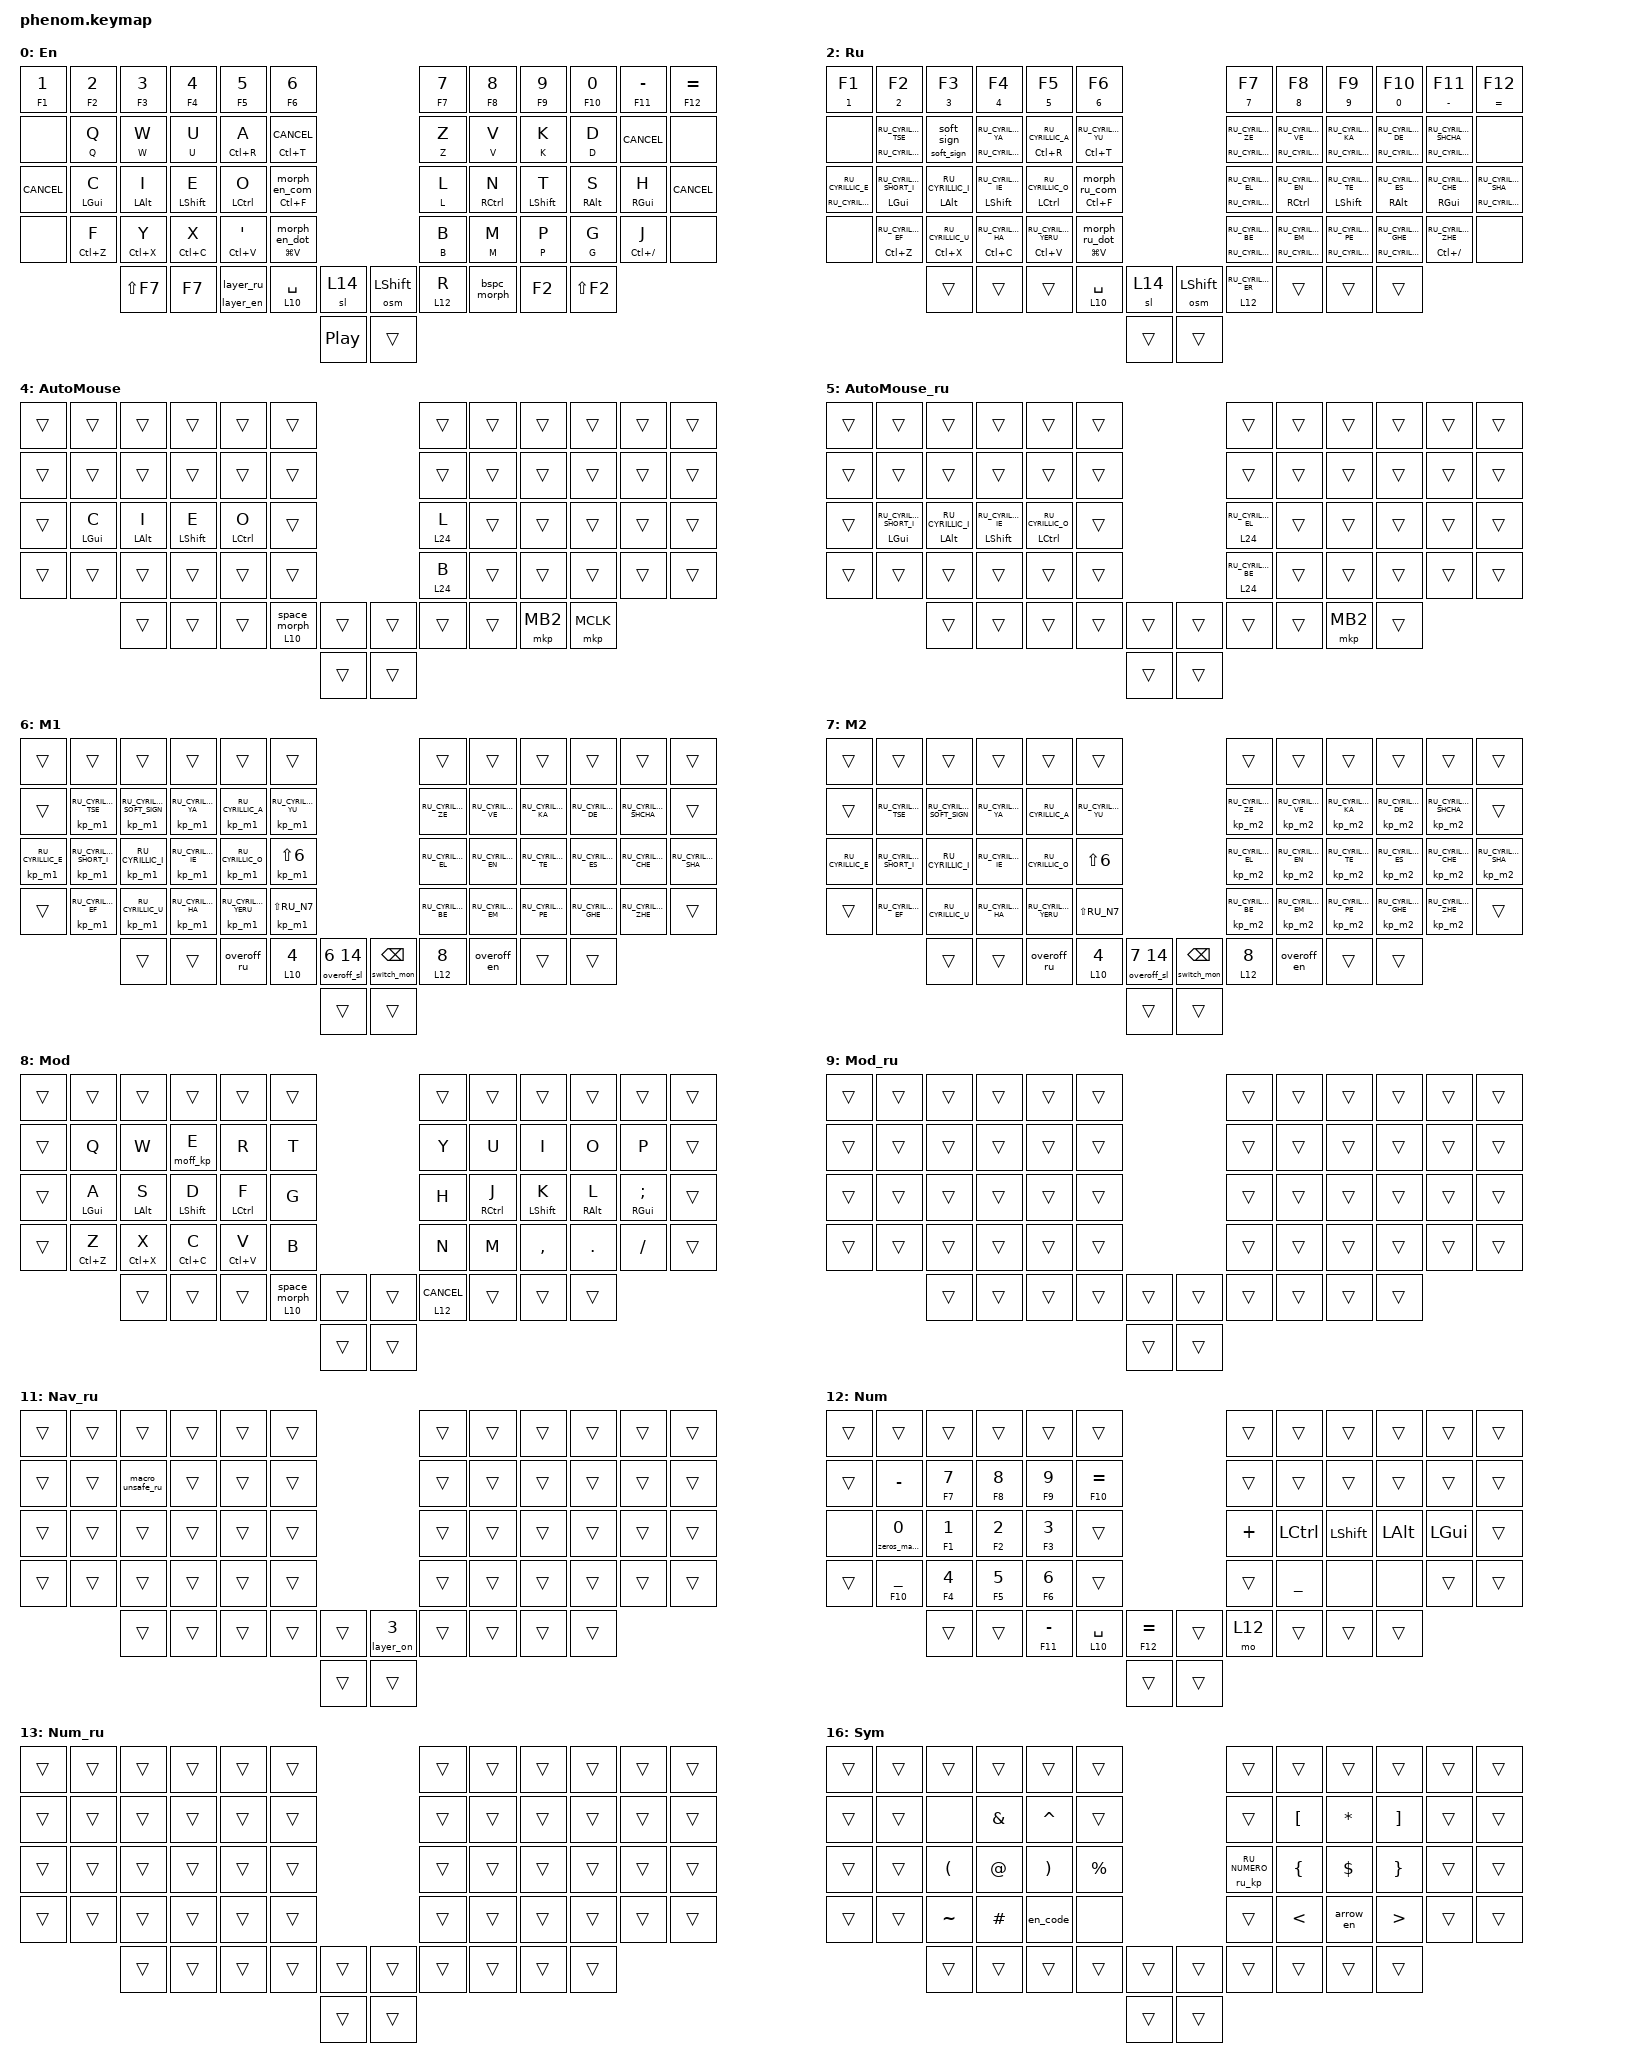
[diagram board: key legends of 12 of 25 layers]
#include "keys_ru.h"
#include <dt-bindings/zmk/behaviors.h>
#include <dt-bindings/zmk/input_transform.h>
#include <behaviors/mouse_key_toggle.dtsi>
#include <input/processors.dtsi>
#include <zephyr/dt-bindings/input/input-event-codes.h>
#include <zmk-input-inertia/input/processor/input_inertia.dtsi>
#include <behaviors.dtsi>
#include <dt-bindings/zmk/bt.h>
#include <dt-bindings/zmk/keys.h>
#include <dt-bindings/zmk/outputs.h>
#include <dt-bindings/zmk/pointing.h>

#define ZMK_POINTING_DEFAULT_SCRL_VAL 20
#define ZMK_POINTING_DEFAULT_MOVE_VAL 125

&mt {
    flavor = "tap-preferred";
    bindings = <&moff_tap>, <&moff_tap>;

    tapping-term-ms = <200>;
};

&lt {
    flavor = "balanced";
    bindings = <&mo>, <&moff_tap>;

    tapping-term-ms = <200>;
};

&sl {
    release-after-ms = <5000>;
    ignore-modifiers;
};

&sk {
    release-after-ms = <30000>;
    quick-release;
};

&msc {
    acceleration-exponent = <0>;
    time-to-max-speed-ms = <50>;
};

&mmv {
    acceleration-exponent = <0>;
    time-to-max-speed-ms = <50>;
};

&key_repeat { usage-pages = <HID_USAGE_KEY HID_USAGE_CONSUMER>; };

/ {
    combos {
        compatible = "zmk,combos";

        combo_ctrl_ent {
            bindings = <&long_kp LC(ENTER)>;
            key-positions = <>;
            require-prior-idle-ms = <30>;
        };

        combo_enter {
            bindings = <&long_kp ENTER>;
            key-positions = <>;
            require-prior-idle-ms = <30>;
        };

        combo_tab {
            bindings = <&long_kp TAB>;
            key-positions = <>;
            require-prior-idle-ms = <30>;
            timeout-ms = <30>;
        };

        combo_esc {
            bindings = <&kp_overoff ESC>;
            key-positions = <>;
            require-prior-idle-ms = <30>;
        };

        combo_ru {
            bindings = <&layer_ru>;
            key-positions = <>;
            require-prior-idle-ms = <30>;
            timeout-ms = <30>;
        };

        combo_en {
            bindings = <&layer_en>;
            key-positions = <>;
            require-prior-idle-ms = <30>;
            timeout-ms = <30>;
        };

        combo_osl_sym_en {
            bindings = <&sl 16>;
            key-positions = <>;
            require-prior-idle-ms = <50>;
            layers = <0 1 16>;
            timeout-ms = <30>;
        };

        combo_lessgreater_en {
            bindings = <&less_greater_en>;
            require-prior-idle-ms = <20>;
            key-positions = <43 45>;
            layers = <0 1 16 4>;
        };

        combo_osl_sym_ru {
            bindings = <&sl 17>;
            key-positions = <>;
            require-prior-idle-ms = <50>;
            layers = <2 3 17>;
            timeout-ms = <30>;
        };

        combo_lessgreater_ru {
            bindings = <&less_greater_ru>;
            key-positions = <43 45>;
            require-prior-idle-ms = <30>;
            layers = <2 3>;
        };

        combo_braces_en {
            bindings = <&braces_en>;
            key-positions = <31 33>;
            require-prior-idle-ms = <20>;
            layers = <0 1 16 4>;
            timeout-ms = <30>;
        };

        combo_asterisk_ru {
            bindings = <&kp RU_ASTERISK>;
            key-positions = <>;
            layers = <2 3 17 13 5>;
        };

        combo_asterisk_en {
            bindings = <&kp ASTERISK>;
            key-positions = <>;
            layers = <0 1 12 16 4>;
        };

        combo_capsword_en {
            bindings = <&layer_on 1>;
            key-positions = <>;
            layers = <0 1>;
        };

        combo_osl_fn {
            bindings = <&sl 18>;
            key-positions = <38 40>;
        };

        combo_osl_os {
            bindings = <&sl 19>;
            key-positions = <37 38>;
        };

        combo_capsword_ru {
            bindings = <&layer_on 3>;
            key-positions = <>;
            layers = <2 3>;
        };

        combo_minus {
            bindings = <&kp MINUS>;
            key-positions = <>;
        };

        parentheses {
            bindings = <&parentheses>;
            key-positions = <26 28>;
            require-prior-idle-ms = <20>;
            timeout-ms = <30>;
        };

        combo_braces_ru {
            bindings = <&braces_ru>;
            key-positions = <31 33>;
            layers = <2 3 17 5>;
            require-prior-idle-ms = <20>;
            timeout-ms = <30>;
        };

        combo_brackets_en {
            bindings = <&brackets_en>;
            key-positions = <19 21>;
            layers = <0 1 16 4>;
            timeout-ms = <30>;
            require-prior-idle-ms = <30>;
        };

        combo_brackets_ru {
            bindings = <&brackets_ru>;
            key-positions = <19 21>;
            layers = <2 3 17 5>;
        };

        combo_equal {
            bindings = <&kp EQUAL>;
            key-positions = <>;
        };

        combo_quotes_en {
            bindings = <&quote_morph_en>;
            key-positions = <44 43>;
            layers = <0 1 12 16 4 8 10 14 19>;
        };

        combo_quotes_ru {
            bindings = <&quote_morph_ru>;
            key-positions = <43 44>;
            layers = <2 3 17 13 9 5 11 15 20>;
        };

        combo_slash_ru {
            bindings = <&slash_morph_ru>;
            key-positions = <19 20>;
            layers = <2 3 13 17 5 9 11 15 20>;
        };

        combo_slash_en {
            bindings = <&slash_morph_en>;
            key-positions = <19 20>;
            layers = <0 1 12 16 4 8 10 14 19>;
        };

        combo_arrow_ru {
            bindings = <&arrow_ru>;
            key-positions = <>;
            layers = <2 3 13 17 5 9 11 15 20>;
        };

        combo_arrow_en {
            bindings = <&arrow_en>;
            key-positions = <>;
            layers = <0 1 12 16 4 8 10 14 19>;
        };

        combo_mclick {
            bindings = <&mkp MB3>;
            key-positions = <15 14>;
            layers = <4 5 14 15 23>;
            timeout-ms = <50>;
        };

        combo_lclick {
            bindings = <&click>;
            key-positions = <>;
            layers = <4 5 14 15 23>;
            timeout-ms = <50>;
        };

        combo_rclick {
            bindings = <&mkp MB2>;
            key-positions = <39 38>;
            layers = <4 5 14 15 23>;
            timeout-ms = <50>;
        };

        combo_shft_click {
            bindings = <&mod_click LEFT_SHIFT>;
            key-positions = <>;
            layers = <4 5 14 15>;
            timeout-ms = <50>;
        };

        combo_cmd_click {
            bindings = <&mod_click LCTRL>;
            key-positions = <>;
            layers = <4 5 14 15 23>;
            timeout-ms = <50>;
        };

        combo_cmd_shift_click {
            bindings = <&mod_click LS(LCTRL)>;
            key-positions = <>;
            layers = <4 5 14 15 23>;
            timeout-ms = <50>;
        };

        combo_grave_en {
            bindings = <&kp GRAVE>;
            key-positions = <43 44 45>;
            layers = <0 1 12 16 4 8 10 14 19>;
        };

        combo_pipe_en {
            bindings = <&kp PIPE>;
            key-positions = <19 20 21>;
            layers = <0 1 12 16 4 8 10 14 19>;
        };

        combo_squote_en {
            bindings = <&kp SINGLE_QUOTE>;
            key-positions = <44 45>;
            layers = <0 1 12 16 4 8 10 14 19>;
        };

        combo_bslash_en {
            bindings = <&kp BACKSLASH>;
            key-positions = <20 21>;
            layers = <0 1 12 16 4 8 10 14 19>;
        };

        combo_bslash_ru {
            bindings = <&kp RU_BACKSLASH>;
            key-positions = <20 21>;
            layers = <2 3 13 17 5 9 11 15 20>;
        };

        combo_pipe_ru {
            bindings = <&en_kp PIPE>;
            key-positions = <20 21 19>;
            layers = <2 3 13 17 5 9 11 15 20>;
        };

        combo_squote_ru {
            bindings = <&en_kp SINGLE_QUOTE>;
            key-positions = <44 45>;
            layers = <2 3 13 17 5 9 11 15 20>;
        };

        combo_grave_ru {
            bindings = <&en_kp GRAVE>;
            key-positions = <44 45 43>;
            layers = <2 3 13 17 5 9 11 15 20>;
        };

        combo_colon_ru {
            bindings = <&kp RU_COLON>;
            key-positions = <38 39 40>;
            layers = <2 3 13 17 5 9 11 15 20>;
        };

        combo_semi_ru {
            bindings = <&kp RU_SEMI>;
            key-positions = <26 27 28>;
            layers = <2 3 13 17 5 9 11 15 20>;
        };

        combo_colon_en {
            bindings = <&kp COLON>;
            key-positions = <38 40 39>;
            layers = <0 1 12 16 4 8 10 14 19>;
        };

        combo_semi_en {
            bindings = <&kp SEMI>;
            key-positions = <26 27 28>;
            layers = <0 1 12 16 4 8 10 14 19>;
        };
    };

    macros {
        layer_ru: layer_ru {
            compatible = "zmk,behavior-macro";
            #binding-cells = <0>;
            bindings = <&to 2>, <&macro_tap_time 50>, <&kp LS(LC(N8))>;

            label = "LAYER_RU";
            tap-ms = <1>;
            wait-ms = <0>;
        };

        layer_en: layer_en {
            compatible = "zmk,behavior-macro";
            #binding-cells = <0>;
            bindings = <&to 0>, <&macro_tap_time 50>, <&kp LS(LC(N9))>;

            label = "LAYER_EN";
            tap-ms = <1>;
            wait-ms = <0>;
        };

        lg_ru: lg_ru {
            compatible = "zmk,behavior-macro";
            #binding-cells = <0>;
            bindings = <&kp LS(LC(N8))>;
            label = "LG_RU";
            tap-ms = <50>;
        };

        lg_en: lg_en {
            compatible = "zmk,behavior-macro";
            #binding-cells = <0>;
            bindings = <&kp LS(LC(N9))>;
            label = "LG_EN";
            tap-ms = <50>;
        };

        en_kp: en_kp {
            compatible = "zmk,behavior-macro-one-param";
            #binding-cells = <1>;
            bindings = <&kp LS(LC(N9)) &macro_param_1to1 &kp MACRO_PLACEHOLDER &kp LS(LC(N8))>;
            label = "EN_KP";
            tap-ms = <50>;
        };

        ru_kp: ru_kp {
            compatible = "zmk,behavior-macro-one-param";
            #binding-cells = <1>;
            bindings = <&kp LS(LC(N8)) &macro_param_1to1 &kp MACRO_PLACEHOLDER &kp LS(LC(N9))>;
            label = "RU_KP";
            tap-ms = <50>;
        };

        mouse_off: mouse_off {
            compatible = "zmk,behavior-macro";
            #binding-cells = <0>;
            bindings = <&kp LC(LS(F9))>;
            label = "MOUSE_OFF";
        };

        free: free {
            compatible = "zmk,behavior-macro";
            #binding-cells = <0>;
            bindings = <&kp LC(LS(F10))>;
            label = "FREE";
        };

        overlay: overlay {
            compatible = "zmk,behavior-macro";
            #binding-cells = <0>;
            bindings = <&kp LC(LS(F11))>;
            label = "OVERLAY";
        };

        en_code: en_code_block {
            compatible = "zmk,behavior-macro";
            #binding-cells = <0>;
            bindings = <&kp GRAVE &kp GRAVE &kp GRAVE &kp RETURN &kp RET &kp GRAVE &kp GRAVE &kp GRAVE &kp HOME &kp LEFT>;
            label = "EN_CODE_BLOCK";
            tap-ms = <50>;
        };

        ru_code: ru_code {
            compatible = "zmk,behavior-macro";
            #binding-cells = <0>;
            bindings = <&lg_en &kp GRAVE &kp GRAVE &kp GRAVE &kp RETURN &kp RET &kp GRAVE &kp GRAVE &kp GRAVE &kp HOME &kp LEFT &lg_ru>;
            label = "RU_CODE";
            tap-ms = <50>;
            wait-ms = <10>;
        };

        ru_cw_off: ru_cw_off {
            compatible = "zmk,behavior-macro-one-param";
            #binding-cells = <1>;
            bindings = <&to 2 &macro_param_1to1 &kp MACRO_PLACEHOLDER>;
            label = "RU_CW_OFF";
            wait-ms = <0>;
            tap-ms = <0>;
        };

        en_cw_off: en_cw_off {
            compatible = "zmk,behavior-macro-one-param";
            #binding-cells = <1>;
            bindings = <&to 0 &macro_param_1to1 &kp MACRO_PLACEHOLDER>;
            label = "EN_CW_OFF";
            wait-ms = <0>;
            tap-ms = <0>;
        };

        zeros_macro: zeros_macro {
            compatible = "zmk,behavior-macro";
            #binding-cells = <0>;
            bindings = <&kp N0 &kp N0 &kp N0 &kp N0 &kp N0 &kp N0>;
            label = "ZEROS_MACRO";
        };

        ml: ml {
            compatible = "zmk,behavior-macro-one-param";
            #binding-cells = <1>;
            bindings =
                <&layer_off 4 &layer_on 8 &macro_param_1to1 &key_on MACRO_PLACEHOLDER>,
                <&macro_pause_for_release>,
                <&macro_param_1to1 &key_off MACRO_PLACEHOLDER &layer_off 8>;

            label = "ML";
            wait-ms = <0>;
            tap-ms = <0>;
        };

        braces_en: braces_en {
            compatible = "zmk,behavior-macro";
            #binding-cells = <0>;
            bindings =
                <&kp LEFT_BRACE &kp RIGHT_BRACE &kp LEFT>,
                <&macro_tap_time 1>,
                <&layer_off 4>;

            label = "BRACES_EN";
            tap-ms = <50>;
        };

        braces_ru: braces_ru {
            compatible = "zmk,behavior-macro";
            #binding-cells = <0>;
            bindings =
                <&lg_en &kp LEFT_BRACE &kp RIGHT_BRACE &kp LEFT &lg_ru>,
                <&macro_tap_time 1>,
                <&layer_off 4>;

            label = "BRACES_RU";
            tap-ms = <50>;
        };

        brackets_en: brackets_en {
            compatible = "zmk,behavior-macro";
            #binding-cells = <0>;
            bindings =
                <&kp LEFT_BRACKET &kp RIGHT_BRACKET &kp LEFT_ARROW>,
                <&macro_tap_time 1>,
                <&layer_off 4>;

            label = "BRACKETS_EN";
            tap-ms = <50>;
        };

        brackets_ru: brackets_ru {
            compatible = "zmk,behavior-macro";
            #binding-cells = <0>;
            bindings =
                <&lg_en &kp LEFT_BRACKET &kp RIGHT_BRACKET &kp LEFT_ARROW &lg_ru>,
                <&macro_tap_time 1>,
                <&layer_off 4>;

            label = "BRACKETS_RU";
            tap-ms = <50>;
        };

        parentheses: parentheses {
            compatible = "zmk,behavior-macro";
            #binding-cells = <0>;
            bindings =
                <&kp LEFT_PARENTHESIS &kp RIGHT_PARENTHESIS &kp LEFT_ARROW>,
                <&macro_tap_time 1>,
                <&layer_off 4>;

            label = "PARENTHESES";
            tap-ms = <50>;
        };

        less_greater_en: less_greater_en {
            compatible = "zmk,behavior-macro";
            #binding-cells = <0>;
            bindings =
                <&kp LESS_THAN &kp GREATER_THAN &kp LEFT>,
                <&macro_tap_time 1>,
                <&layer_off 4>;

            label = "LESS_GREATER_EN";
            tap-ms = <50>;
        };

        less_greater_ru: less_greater_ru {
            compatible = "zmk,behavior-macro";
            #binding-cells = <0>;
            bindings =
                <&lg_en &kp LESS_THAN &kp GREATER_THAN &kp LEFT_ARROW &lg_ru>,
                <&macro_press>,
                <&layer_off 4>;

            label = "LESS_GREATER_RU";
            tap-ms = <50>;
        };

        alt_spc_ru: alt_spc_ru {
            compatible = "zmk,behavior-macro";
            #binding-cells = <0>;
            bindings = <&kp LA(SPACE) &layer_en>;
            label = "ALT_SPC_RU";
        };

        testops: testops {
            compatible = "zmk,behavior-macro";
            #binding-cells = <0>;
            bindings =
                <&kp LS(LC(LG(F7)))>,
                <&macro_wait_time 100>,
                <&kp LEFT_ARROW &kp LS(LC(LG(F8)))>;

            label = "TESTOPS";
            wait-ms = <350>;
            tap-ms = <150>;
        };

        long_kp: long_kp {
            compatible = "zmk,behavior-macro-one-param";
            #binding-cells = <1>;
            bindings =
                <&macro_press>,
                <&macro_param_1to1 &kp MACRO_PLACEHOLDER>,
                <&macro_pause_for_release>,
                <&macro_release>,
                <&macro_param_1to1 &kp MACRO_PLACEHOLDER>;

            label = "LONG_KP";
            wait-ms = <40>;
        };

        bt_set: bt_set {
            compatible = "zmk,behavior-macro-one-param";
            #binding-cells = <1>;
            bindings = <&out OUT_BLE &macro_param_1to2 &bt BT_SEL MACRO_PLACEHOLDER>;
            label = "BT_SET";
            tap-ms = <20>;
        };

        arrow_en: arrow_en {
            compatible = "zmk,behavior-macro";
            #binding-cells = <0>;
            bindings =
                <&kp MINUS &kp GREATER_THAN>,
                <&macro_tap_time 1>,
                <&layer_off 4>;

            label = "ARROW_EN";
            tap-ms = <50>;
        };

        arrow_ru: arrow_ru {
            compatible = "zmk,behavior-macro";
            #binding-cells = <0>;
            bindings =
                <&lg_en &arrow_en &lg_ru>,
                <&macro_tap_time 1>,
                <&layer_off 4>;

            label = "ARROW_RU";
            tap-ms = <50>;
        };

        bt_set_en: bt_set_en {
            compatible = "zmk,behavior-macro-one-param";
            #binding-cells = <1>;
            bindings = <&macro_param_1to1 &bt_set MACRO_PLACEHOLDER &layer_off 19 &lg_en &lg_en>;
            label = "BT_SET_en";
            wait-ms = <45>;
            tap-ms = <50>;
        };

        one_shot: one_shot {
            compatible = "zmk,behavior-macro-one-param";
            #binding-cells = <1>;
            bindings =
                <&macro_param_1to1 &sk MACRO_PLACEHOLDER>,
                <&macro_pause_for_release>,
                <&kp K_CANCEL>;

            label = "ONE_SHOT";
            tap-ms = <1>;
            wait-ms = <0>;
        };

        bt_set_ru: bt_set_ru {
            compatible = "zmk,behavior-macro-one-param";
            #binding-cells = <1>;
            bindings = <&macro_param_1to1 &bt_set MACRO_PLACEHOLDER &layer_off 19 &lg_ru &lg_ru>;
            label = "BT_SET_RU";
            wait-ms = <45>;
            tap-ms = <50>;
        };

        vm_lang_ru: vm_lang {
            compatible = "zmk,behavior-macro-one-param";
            #binding-cells = <1>;
            bindings = <&macro_param_1to1 &kp MACRO_PLACEHOLDER &lg_ru &lg_ru>;
            label = "VM_LANG";
            wait-ms = <100>;
            tap-ms = <100>;
        };

        vm_lang_en: vm_lang_en {
            compatible = "zmk,behavior-macro-one-param";
            #binding-cells = <1>;
            bindings = <&macro_param_1to1 &kp MACRO_PLACEHOLDER &lg_en &lg_en>;
            label = "VM_LANG_EN";
            wait-ms = <100>;
            tap-ms = <100>;
        };

        ms_free: ms_free {
            compatible = "zmk,behavior-macro";
            #binding-cells = <0>;
            bindings =
                <&mouse_off>,
                <&macro_tap_time 1>,
                <&layer_on 0 &layer_off 6 &layer_off 7 &layer_off 4>;

            label = "MS_FREE";
            wait-ms = <0>;
        };

        ms_over: ms_over {
            compatible = "zmk,behavior-macro";
            #binding-cells = <0>;
            bindings =
                <&overlay>,
                <&macro_tap_time 1>,
                <&layer_on 6 &layer_off 0 &layer_off 4>;

            label = "MS_OVER";
            wait-ms = <0>;
        };

        kp_to: kp_to {
            compatible = "zmk,behavior-macro-two-param";
            #binding-cells = <2>;
            bindings = <&macro_param_1to1 &kp MACRO_PLACEHOLDER &macro_param_2to1 &to MACRO_PLACEHOLDER>;
            label = "KP_TO";
        };

        kp_m2: kp_m2 {
            compatible = "zmk,behavior-macro-one-param";
            #binding-cells = <1>;
            bindings =
                <&layer_on 0 &layer_off 7>,
                <&macro_tap_time 15>,
                <&macro_param_1to1 &kp MACRO_PLACEHOLDER>;

            label = "KP_M2";
            tap-ms = <1>;
            wait-ms = <0>;
        };

        mouse_back: mouse_back {
            compatible = "zmk,behavior-macro";
            #binding-cells = <0>;
            bindings =
                <&kp TAB>,
                <&macro_tap_time 1>,
                <&layer_on 6 &layer_off 7>;

            label = "MOUSE_BACK";
        };

        alt_spc_en: alt_spc_en {
            compatible = "zmk,behavior-macro";
            #binding-cells = <0>;
            bindings = <&kp LA(SPACE) &layer_en>;
            label = "ALT_SPC_EN";
            tap-ms = <50>;
        };

        kp_free: kp_free {
            compatible = "zmk,behavior-macro-one-param";
            #binding-cells = <1>;
            bindings = <&macro_param_1to1 &kp MACRO_PLACEHOLDER &layer_on 0>;
            label = "KP_FREE";
        };

        kp_m1: kp_m1 {
            compatible = "zmk,behavior-macro-one-param";
            #binding-cells = <1>;
            bindings =
                <&layer_on 7 &layer_off 6>,
                <&macro_tap_time 15>,
                <&macro_param_1to1 &kp MACRO_PLACEHOLDER>;

            label = "KP_M1";
            tap-ms = <1>;
            wait-ms = <0>;
        };

        overoff_sl: overoff_sl {
            compatible = "zmk,behavior-macro-two-param";
            #binding-cells = <2>;
            bindings = <&mouse_off &macro_param_1to1 &layer_off MACRO_PLACEHOLDER &macro_param_2to1 &sl MACRO_PLACEHOLDER>;
            label = "OVEROFF_SL";
        };

        ms_set: ms_set {
            compatible = "zmk,behavior-macro";
            #binding-cells = <0>;
            bindings =
                <&kp SPACE &kp RU_CYRILLIC_I>,
                <&macro_wait_time 0>,
                <&kp RU_CYRILLIC_VE>,
                <&macro_tap_time 1>,
                <&layer_on 0 &layer_off 6 &layer_off 7>;

            label = "MS_SET";
        };

        macro_unsafe_en: macro_unsafe_en {
            compatible = "zmk,behavior-macro";
            #binding-cells = <0>;
            bindings = <&kp T &kp H &kp I &kp S &kp I &kp S &kp U &kp N &kp S &kp A &kp F &kp E>;
            label = "MACRO_UNSAFE_EN";
            wait-ms = <30>;
            tap-ms = <50>;
        };

        macro_unsafe_ru: macro_unsafe_ru {
            compatible = "zmk,behavior-macro";
            #binding-cells = <0>;
            bindings = <&lg_en &kp T &kp H &kp I &kp S &kp I &kp S &kp U &kp N &kp S &kp A &kp F &kp E &lg_ru>;
            label = "MACRO_UNSAFE_RU";
            wait-ms = <30>;
            tap-ms = <50>;
        };

        mml: mml {
            compatible = "zmk,behavior-macro-one-param";
            #binding-cells = <1>;
            bindings =
                <&macro_param_1to1 &key_on MACRO_PLACEHOLDER &layer_on 0>,
                <&macro_pause_for_release>,
                <&macro_param_1to1 &key_off MACRO_PLACEHOLDER &layer_off 0>;

            label = "MML";
            wait-ms = <0>;
            tap-ms = <0>;
        };

        moff_kp: moff_kp {
            compatible = "zmk,behavior-macro-one-param";
            #binding-cells = <1>;
            bindings =
                <&layer_off 4 &macro_param_1to1 &key_on MACRO_PLACEHOLDER>,
                <&macro_pause_for_release>,
                <&macro_param_1to1 &key_off MACRO_PLACEHOLDER>;

            label = "MOFF_KP";
            wait-ms = <0>;
            tap-ms = <0>;
        };

        cmd_scroll: cmd_scroll {
            compatible = "zmk,behavior-macro-one-param";
            #binding-cells = <1>;
            bindings =
                <&macro_press>,
                <&kp LEFT_GUI &macro_param_1to1 &mscl MACRO_PLACEHOLDER>,
                <&macro_pause_for_release>,
                <&macro_release>,
                <&macro_param_1to1 &mscl MACRO_PLACEHOLDER &kp LEFT_GUI>;

            label = "CMD_SCROLL";
            wait-ms = <0>;
        };

        mkpl: mkpl {
            compatible = "zmk,behavior-macro-one-param";
            #binding-cells = <1>;
            bindings =
                <&macro_press>,
                <&macro_param_1to1 &mkp MACRO_PLACEHOLDER>,
                <&macro_pause_for_release>,
                <&macro_release>,
                <&macro_param_1to1 &mkp MACRO_PLACEHOLDER>;

            label = "MKPL";
            wait-ms = <50>;
        };

        mmvl: mmvl {
            compatible = "zmk,behavior-macro-one-param";
            #binding-cells = <1>;
            bindings =
                <&macro_press>,
                <&macro_param_1to1 &mmv MACRO_PLACEHOLDER>,
                <&macro_pause_for_release>,
                <&macro_release>,
                <&macro_param_1to1 &mmv MACRO_PLACEHOLDER>;

            label = "MMVL";
            wait-ms = <125>;
        };

        mscl: mscl {
            compatible = "zmk,behavior-macro-one-param";
            #binding-cells = <1>;
            bindings =
                <&macro_press>,
                <&macro_param_1to1 &msc MACRO_PLACEHOLDER>,
                <&macro_pause_for_release>,
                <&macro_release>,
                <&macro_param_1to1 &msc MACRO_PLACEHOLDER>;

            label = "MSCL";
            wait-ms = <100>;
        };

        mod_layer: mod_layer {
            compatible = "zmk,behavior-macro-two-param";
            #binding-cells = <2>;
            bindings =
                <&macro_param_1to1 &key_on MACRO_PLACEHOLDER &macro_param_2to1 &layer_on MACRO_PLACEHOLDER>,
                <&macro_pause_for_release>,
                <&macro_param_2to1 &layer_off MACRO_PLACEHOLDER &macro_param_1to1 &key_off MACRO_PLACEHOLDER>;

            label = "MOD_LAYER";
            wait-ms = <0>;
            tap-ms = <1>;
        };

        esc_over_off: esc_over_off {
            compatible = "zmk,behavior-macro";
            #binding-cells = <0>;
            bindings =
                <&macro_press>,
                <&long_kp ESC>,
                <&macro_pause_for_release>,
                <&macro_release>,
                <&long_kp ESC>,
                <&macro_tap_time 1>,
                <&layer_off 6 &layer_off 7>;

            label = "ESC_OVER_OFF";
            wait-ms = <0>;
        };

        switch_mon: switch_mon {
            compatible = "zmk,behavior-macro-one-param";
            #binding-cells = <1>;
            bindings = <&macro_param_1to1 &kp MACRO_PLACEHOLDER &layer_on 6 &layer_off 7>;
            label = "SWITCH_MON";
            wait-ms = <0>;
        };

        lkp_moff: lkp_moff {
            compatible = "zmk,behavior-macro-one-param";
            #binding-cells = <1>;
            bindings =
                <&layer_off 4>,
                <&macro_wait_time 30>,
                <&macro_press>,
                <&macro_param_1to1 &kp MACRO_PLACEHOLDER>,
                <&macro_pause_for_release>,
                <&macro_release>,
                <&macro_param_1to1 &kp MACRO_PLACEHOLDER>;

            label = "LKP_MOFF";
            wait-ms = <0>;
            tap-ms = <1>;
        };

        mouse_mod: mouse_mod {
            compatible = "zmk,behavior-macro-one-param";
            #binding-cells = <1>;
            bindings =
                <&macro_press>,
                <&mo 0 &macro_param_1to1 &kp MACRO_PLACEHOLDER>,
                <&macro_pause_for_release>,
                <&macro_release>,
                <&macro_param_1to1 &kp MACRO_PLACEHOLDER &mo 0>;

            label = "MOUSE_MOD";
        };

        left_ctrl: sm_left {
            compatible = "zmk,behavior-macro-one-param";
            #binding-cells = <1>;
            bindings =
                <&macro_press>,
                <&macro_param_1to1 &mo MACRO_PLACEHOLDER &mmvl MOVE_LEFT>,
                <&macro_pause_for_release>,
                <&macro_release>,
                <&mmvl MOVE_LEFT &macro_param_1to1 &mo MACRO_PLACEHOLDER>;

            label = "SM_LEFT";
            wait-ms = <0>;
            tap-ms = <1>;
        };

        down_shift: sm_down {
            compatible = "zmk,behavior-macro-one-param";
            #binding-cells = <1>;
            bindings =
                <&macro_press>,
                <&macro_param_1to1 &mo MACRO_PLACEHOLDER &mdown_morph>,
                <&macro_pause_for_release>,
                <&macro_release>,
                <&mdown_morph &macro_param_1to1 &mo MACRO_PLACEHOLDER>;

            label = "SM_DOWN";
            wait-ms = <0>;
            tap-ms = <1>;
        };

        right_alt: right_alt {
            compatible = "zmk,behavior-macro-one-param";
            #binding-cells = <1>;
            bindings =
                <&macro_press>,
                <&macro_param_1to1 &mo MACRO_PLACEHOLDER &mright_morph>,
                <&macro_pause_for_release>,
                <&macro_release>,
                <&mright_morph &macro_param_1to1 &mo MACRO_PLACEHOLDER>;

            label = "RIGHT_ALT";
            wait-ms = <0>;
            tap-ms = <1>;
        };

        over_ms_free: over_ms_free {
            compatible = "zmk,behavior-macro";
            #binding-cells = <0>;
            bindings = <&mouse_off>, <&macro_tap_time 1>, <&ms_free>;

            label = "OVER_MS_FREE";
            wait-ms = <0>;
        };

        kp_overoff: esc_msoff {
            compatible = "zmk,behavior-macro-one-param";
            #binding-cells = <1>;
            bindings =
                <&layer_off 6 &layer_off 7>,
                <&macro_tap_time 75>,
                <&macro_param_1to1 &kp MACRO_PLACEHOLDER>;

            label = "ESC_MSOFF";
            wait-ms = <0>;
            tap-ms = <1>;
        };

        overoff_ru: overoff_ru {
            compatible = "zmk,behavior-macro";
            #binding-cells = <0>;
            bindings =
                <&mouse_off>,
                <&macro_tap_time 1>,
                <&to 2>,
                <&macro_tap_time 30>,
                <&kp LS(LC(N8))>;

            label = "OVEROFF_RU";
        };

        overoff_en: overoff_en {
            compatible = "zmk,behavior-macro";
            #binding-cells = <0>;
            bindings =
                <&mouse_off>,
                <&macro_tap_time 1>,
                <&to 0>,
                <&macro_tap_time 30>,
                <&kp LS(LC(N9))>;

            label = "OVEROFF_EN";
        };

        mod_click: mod_click {
            compatible = "zmk,behavior-macro-one-param";
            #binding-cells = <1>;
            bindings = <&macro_param_1to1 &key_on MACRO_PLACEHOLDER &mkp LCLK &macro_param_1to1 &key_off MACRO_PLACEHOLDER>;
            label = "MOD_CLICK";
        };

        mkp_moff: mkp_moff {
            compatible = "zmk,behavior-macro-one-param";
            #binding-cells = <1>;
            bindings =
                <&layer_off 4>,
                <&macro_wait_time 40>,
                <&macro_press>,
                <&macro_param_1to1 &mkp MACRO_PLACEHOLDER>,
                <&macro_pause_for_release>,
                <&macro_release>,
                <&macro_param_1to1 &mkp MACRO_PLACEHOLDER>;

            label = "MKP_MOFF";
            tap-ms = <1>;
            wait-ms = <0>;
        };

        osm: osm {
            compatible = "zmk,behavior-macro-one-param";
            #binding-cells = <1>;
            bindings =
                <&macro_param_1to1 &sk MACRO_PLACEHOLDER>,
                <&macro_pause_for_release>;

            label = "OSM";
            tap-ms = <1>;
            wait-ms = <0>;
        };

        tap: tap {
            compatible = "zmk,behavior-macro-one-param";
            #binding-cells = <1>;
            bindings =
                <&macro_param_1to1 &kp MACRO_PLACEHOLDER>,
                <&macro_pause_for_release>;

            label = "TAP";
            tap-ms = <30>;
        };

        moff_tap: moff_tap {
            compatible = "zmk,behavior-macro-one-param";
            #binding-cells = <1>;
            bindings =
                <&layer_off 4>,
                <&macro_tap_time 100>,
                <&macro_param_1to1 &kp MACRO_PLACEHOLDER>,
                <&macro_pause_for_release>;

            label = "MOFF_TAP";
            tap-ms = <0>;
            wait-ms = <0>;
        };

        click: click {
            compatible = "zmk,behavior-macro";
            #binding-cells = <0>;
            bindings =
                <&macro_press>,
                <&mo 21 &mkp MB1>,
                <&macro_pause_for_release>,
                <&macro_release>,
                <&mkp MB1 &mo 21>;

            label = "CLICK";
            wait-ms = <0>;
            tap-ms = <0>;
        };
    };

    behaviors {
        layer_off: layer_off {
            compatible = "zmk,behavior-toggle-layer";
            label = "LAYER_OFF";
            #binding-cells = <1>;
            toggle-mode = "off";
        };

        hrm: hrm {
            compatible = "zmk,behavior-hold-tap";
            label = "HRM";
            bindings = <&kp>, <&kp>;

            #binding-cells = <2>;
            tapping-term-ms = <200>;
            flavor = "balanced";
            hold-while-undecided;
        };

        hrm_slow: hrm_slow {
            compatible = "zmk,behavior-hold-tap";
            label = "HRM_SLOW";
            bindings = <&kp>, <&kp>;

            #binding-cells = <2>;
            flavor = "balanced";
            tapping-term-ms = <200>;
            hold-while-undecided;
        };

        ru_lt_cw_off: ru_lt_cw_off {
            compatible = "zmk,behavior-hold-tap";
            label = "RU_LT_CW_OFF";
            bindings = <&mo>, <&ru_cw_off>;

            #binding-cells = <2>;
            tapping-term-ms = <200>;
            flavor = "balanced";
        };

        en_lt_cw_off: en_lt_cw_off {
            compatible = "zmk,behavior-hold-tap";
            label = "EN_LT_CW_OFF";
            bindings = <&mo>, <&en_cw_off>;

            #binding-cells = <2>;
            tapping-term-ms = <200>;
            flavor = "balanced";
        };

        bspc_morph: bspc_morph {
            compatible = "zmk,behavior-mod-morph";
            label = "BSPC_MORPH";
            bindings = <&kp BACKSPACE>, <&kp DELETE>;

            #binding-cells = <0>;
            mods = <(MOD_LALT)>;
        };

        key_on: key_on {
            compatible = "zmk,behavior-key-toggle";
            label = "KEY_ON";
            #binding-cells = <1>;
        };

        key_off: key_off {
            compatible = "zmk,behavior-key-toggle";
            label = "KEY_OFF";
            #binding-cells = <1>;
            toggle-mode = "off";
        };

        hrml: hrml {
            compatible = "zmk,behavior-hold-tap";
            label = "HRML";
            bindings = <&ml>, <&moff_kp>;

            #binding-cells = <2>;
            tapping-term-ms = <200>;
            flavor = "balanced";
            hold-trigger-key-positions = <13 14 17 25 26 27 28 29 37 38 39 40 41 15 18 19 21 22 30 31 32 33 34 42 43 44 45 46 20 51 55 54>;
        };

        layer_on: layer_on {
            compatible = "zmk,behavior-toggle-layer";
            label = "LAYER_ON";
            #binding-cells = <1>;
            toggle-mode = "on";
        };

        hrml_slow: hrml_slow {
            compatible = "zmk,behavior-hold-tap";
            label = "HRML_SLOW";
            bindings = <&ml>, <&moff_tap>;

            #binding-cells = <2>;
            tapping-term-ms = <200>;
            flavor = "tap-preferred";
        };

        soft_sign: soft_sign {
            compatible = "zmk,behavior-mod-morph";
            label = "SOFT_SIGN";
            bindings =
                <&moff_kp RU_CYRILLIC_SOFT_SIGN>,
                <&moff_kp RU_CYRILLIC_HARD_SIGN>;

            #binding-cells = <0>;
            mods = <(MOD_LSFT)>;
        };

        en_dot_excl: en_dot_excl {
            compatible = "zmk,behavior-mod-morph";
            label = "EN_DOT_EXCL";
            bindings = <&morph_en_dot>, <&en_cw_off COLON>;

            #binding-cells = <0>;
            mods = <(MOD_RALT|MOD_RGUI)>;
        };

        en_com_ques: en_com_ques {
            compatible = "zmk,behavior-mod-morph";
            label = "EN_COM_QUES";
            bindings = <&morph_en_com>, <&en_cw_off SEMI>;

            #binding-cells = <0>;
            mods = <(MOD_RALT|MOD_RGUI)>;
        };

        ru_dot_excl: ru_dot_excl {
            compatible = "zmk,behavior-mod-morph";
            label = "RU_DOT_EXCL";
            bindings = <&morph_ru_dot>, <&ru_cw_off RU_COLON>;

            #binding-cells = <0>;
            mods = <(MOD_RALT|MOD_RGUI)>;
        };

        ru_com_ques: ru_com_ques {
            compatible = "zmk,behavior-mod-morph";
            label = "RU_COM_QUES";
            bindings = <&morph_ru_com>, <&ru_cw_off RU_SEMI>;

            #binding-cells = <0>;
            mods = <(MOD_RALT|MOD_RGUI)>;
        };

        ru_dot_mt: ru_dot_mt {
            compatible = "zmk,behavior-hold-tap";
            label = "RU_DOT_MT";
            bindings = <&moff_tap>, <&morph_ru_dot>;

            #binding-cells = <2>;
            tapping-term-ms = <200>;
            flavor = "tap-preferred";
        };

        ru_com_mt: ru_com_mt {
            compatible = "zmk,behavior-hold-tap";
            label = "RU_COM_MT";
            bindings = <&moff_tap>, <&morph_ru_com>;

            #binding-cells = <2>;
            tapping-term-ms = <200>;
            flavor = "tap-preferred";
        };

        en_com_mt: en_com_mt {
            compatible = "zmk,behavior-hold-tap";
            label = "EN_COM_MT";
            bindings = <&moff_tap>, <&morph_en_com>;

            #binding-cells = <2>;
            tapping-term-ms = <200>;
            flavor = "balanced";
        };

        en_dot_mt: en_dot_mt {
            compatible = "zmk,behavior-hold-tap";
            label = "EN_DOT_MT";
            bindings = <&moff_tap>, <&morph_en_dot>;

            #binding-cells = <2>;
            tapping-term-ms = <200>;
            flavor = "balanced";
        };

        space_morph: space_morph {
            compatible = "zmk,behavior-mod-morph";
            label = "SPACE_MORPH";
            bindings = <&moff_tap SPACE>, <&moff_tap TAB>;

            #binding-cells = <0>;
            mods = <(MOD_RSFT|MOD_LALT|MOD_LSFT|MOD_RALT|MOD_LCTL|MOD_RGUI|MOD_RCTL|MOD_LGUI)>;
            keep-mods = <(MOD_LSFT|MOD_RSFT|MOD_LALT|MOD_RALT|MOD_LCTL|MOD_RGUI|MOD_LGUI|MOD_RCTL)>;
        };

        caps_soft_sign: caps_soft_sign {
            compatible = "zmk,behavior-mod-morph";
            label = "CAPS_SOFT_SIGN";
            bindings =
                <&moff_kp LS(RU_CYRILLIC_SOFT_SIGN)>,
                <&moff_kp LS(RU_CYRILLIC_HARD_SIGN)>;

            #binding-cells = <0>;
            mods = <(MOD_LSFT)>;
        };

        space_lt: space_lt {
            compatible = "zmk,behavior-hold-tap";
            label = "SPACE_LT";
            bindings = <&mo>, <&space_morph>;

            #binding-cells = <2>;
            tapping-term-ms = <200>;
            flavor = "balanced";
        };

        mod_dtap: mod_dtap {
            compatible = "zmk,behavior-hold-tap";
            label = "MOD_DTAP";
            bindings = <&kp>, <&kp>;

            #binding-cells = <2>;
            tapping-term-ms = <200>;
            flavor = "hold-preferred";
        };

        hrosm_l: hrosm_l {
            compatible = "zmk,behavior-hold-tap";
            label = "HROSM_L";
            bindings = <&moff_kp>, <&moff_kp>;

            #binding-cells = <2>;
            tapping-term-ms = <200>;
            flavor = "balanced";
            hold-trigger-key-positions = <18 30 42 43 44 45 54 31 19 20 32 21 33 34 22 46 35 53>;
        };

        hrosm_r: hrosm_r {
            compatible = "zmk,behavior-hold-tap";
            label = "HROSM_R";
            bindings = <&kp>, <&moff_tap>;

            #binding-cells = <2>;
            tapping-term-ms = <200>;
            flavor = "balanced";
        };

        vm_en: vm_en {
            compatible = "zmk,behavior-hold-tap";
            label = "VM_EN";
            bindings = <&vm_lang_en>, <&vm_lang_en>;

            #binding-cells = <2>;
            tapping-term-ms = <200>;
            flavor = "tap-preferred";
        };

        vm_ru: vm_ru {
            compatible = "zmk,behavior-hold-tap";
            label = "VM_RU";
            bindings = <&vm_lang_ru>, <&vm_lang_ru>;

            #binding-cells = <2>;
            tapping-term-ms = <200>;
            flavor = "tap-preferred";
        };

        back_num: back_num {
            compatible = "zmk,behavior-hold-tap";
            label = "BACK_NUM";
            bindings = <&mo>, <&mouse_back>;

            #binding-cells = <2>;
            tapping-term-ms = <200>;
            flavor = "balanced";
        };

        slash_morph_ru: slash_morph_ru {
            compatible = "zmk,behavior-mod-morph";
            label = "SLASH_MORPH_RU";
            bindings = <&morph_pipe_ru>, <&kp RU_BACKSLASH>;

            #binding-cells = <0>;
            mods = <(MOD_LSFT)>;
        };

        slash_morph_en: slash_morph_en {
            compatible = "zmk,behavior-mod-morph";
            label = "SLASH_MORPH_EN";
            bindings = <&morph_pipe_en>, <&kp BACKSLASH>;

            #binding-cells = <0>;
            mods = <(MOD_LSFT)>;
        };

        quote_morph_ru: quote_morph_ru {
            compatible = "zmk,behavior-mod-morph";
            label = "QUOTE_MORPH_RU";
            bindings = <&kp RU_DOUBLE_QUOTES>, <&en_kp SINGLE_QUOTE>;

            #binding-cells = <0>;
            mods = <(MOD_LSFT)>;
        };

        quote_morph_en: quote_morph_en {
            compatible = "zmk,behavior-mod-morph";
            label = "QUOTE_MORPH_EN";
            bindings = <&kp DOUBLE_QUOTES>, <&kp SINGLE_QUOTE>;

            #binding-cells = <0>;
            mods = <(MOD_LSFT)>;
        };

        morph_en_dot: morph_en_dot {
            compatible = "zmk,behavior-mod-morph";
            label = "MORPH_EN_DOT";
            bindings = <&en_cw_off DOT>, <&en_cw_off EXCL>;

            #binding-cells = <0>;
            mods = <(MOD_LSFT)>;
        };

        morph_en_com: morph_en_com {
            compatible = "zmk,behavior-mod-morph";
            label = "MORPH_EN_COM";
            bindings = <&en_cw_off COMMA>, <&en_cw_off QUESTION>;

            #binding-cells = <0>;
            mods = <(MOD_LSFT)>;
        };

        morph_ru_dot: morph_ru_dot {
            compatible = "zmk,behavior-mod-morph";
            label = "MORPH_RU_DOT";
            bindings = <&ru_cw_off RU_DOT>, <&ru_cw_off RU_EXCL>;

            #binding-cells = <0>;
            mods = <(MOD_LSFT)>;
        };

        morph_ru_com: morph_ru_com {
            compatible = "zmk,behavior-mod-morph";
            label = "MORPH_RU_COM";
            bindings = <&ru_cw_off RU_COMMA>, <&ru_cw_off RU_QUESTION>;

            #binding-cells = <0>;
            mods = <(MOD_LSFT)>;
        };

        morph_quotes_ru: morph_quotes_ru {
            compatible = "zmk,behavior-mod-morph";
            label = "MORPH_QUOTES_RU";
            bindings = <&kp RU_DQT>, <&en_kp GRAVE>;

            #binding-cells = <0>;
            mods = <(MOD_RALT|MOD_LALT)>;
        };

        morph_quotes_en: morph_quotes_en {
            compatible = "zmk,behavior-mod-morph";
            label = "MORPH_QUOTES_EN";
            bindings = <&kp DQT>, <&kp GRAVE>;

            #binding-cells = <0>;
            mods = <(MOD_RALT|MOD_LALT)>;
        };

        morph_pipe_ru: morph_pipe_ru {
            compatible = "zmk,behavior-mod-morph";
            label = "MORPH_PIPE_RU";
            bindings = <&kp RU_SLASH>, <&en_kp PIPE>;

            #binding-cells = <0>;
            mods = <(MOD_LALT|MOD_RALT)>;
        };

        morph_pipe_en: morph_pipe_en {
            compatible = "zmk,behavior-mod-morph";
            label = "MORPH_PIPE_EN";
            bindings = <&kp SLASH>, <&kp PIPE>;

            #binding-cells = <0>;
            mods = <(MOD_RALT|MOD_LALT)>;
        };

        nav_set: nav_set {
            compatible = "zmk,behavior-hold-tap";
            label = "NAV_SET";
            bindings = <&mo>, <&ms_set>;

            #binding-cells = <2>;
            tapping-term-ms = <200>;
            flavor = "balanced";
        };

        mdown_morph: mdown_morph {
            compatible = "zmk,behavior-mod-morph";
            label = "MDOWN_MORPH";
            bindings = <&mmvl MOVE_DOWN>, <&moff_kp K>;

            #binding-cells = <0>;
            mods = <(MOD_LCTL)>;
            keep-mods = <(MOD_LCTL)>;
        };

        mright_morph: mright_morph {
            compatible = "zmk,behavior-mod-morph";
            label = "MRIGHT_MORPH";
            bindings = <&mmvl MOVE_RIGHT>, <&moff_kp L>;

            #binding-cells = <0>;
            mods = <(MOD_LCTL)>;
            keep-mods = <(MOD_LCTL)>;
        };

        ms_space: ms_space {
            compatible = "zmk,behavior-hold-tap";
            label = "MS_SPACE";
            bindings = <&mo>, <&space_morph>;

            #binding-cells = <2>;
            tapping-term-ms = <200>;
            flavor = "balanced";
            hold-while-undecided;
        };

        click_layer: click_layer {
            compatible = "zmk,behavior-sticky-key";
            label = "CLICK_LAYER";
            bindings = <&mo>;
            #binding-cells = <1>;
            release-after-ms = <1000>;
            quick-release;
        };

        zero: zero {
            compatible = "zmk,behavior-hold-tap";
            label = "ZERO";
            bindings = <&zeros_macro>, <&kp>;

            #binding-cells = <2>;
            tapping-term-ms = <200>;
            flavor = "tap-preferred";
        };

        bspc_lt: bspc_lt {
            compatible = "zmk,behavior-hold-tap";
            label = "BSPC_LT";
            bindings = <&mo>, <&bspc_morph>;

            #binding-cells = <2>;
            flavor = "balanced";
            tapping-term-ms = <200>;
        };

        soft: soft {
            compatible = "zmk,behavior-hold-tap";
            label = "SOFT";
            bindings = <&soft_sign>, <&soft_sign>;

            #binding-cells = <2>;
            tapping-term-ms = <200>;
            flavor = "tap-preferred";
        };

        soft_caps: soft_caps {
            compatible = "zmk,behavior-hold-tap";
            label = "SOFT_CAPS";
            bindings = <&caps_soft_sign>, <&caps_soft_sign>;

            #binding-cells = <2>;
            tapping-term-ms = <200>;
            flavor = "tap-preferred";
        };

        mmt: mmt {
            compatible = "zmk,behavior-hold-tap";
            label = "MMT";
            bindings = <&tap>, <&moff_tap>;

            #binding-cells = <2>;
            tapping-term-ms = <220>;
            flavor = "tap-preferred";
        };

        hrml_left: hrml_left {
            compatible = "zmk,behavior-hold-tap";
            label = "HRML_LEFT";
            bindings = <&ml>, <&moff_tap>;

            #binding-cells = <2>;
            tapping-term-ms = <200>;
            flavor = "balanced";
            hold-trigger-key-positions = <40 6 7 8 9 10 11>;
        };

        hrml_right: hrml_right {
            compatible = "zmk,behavior-hold-tap";
            label = "HRML_RIGHT";
            bindings = <&ml>, <&moff_kp>;

            #binding-cells = <2>;
            tapping-term-ms = <200>;
            flavor = "balanced";
            hold-trigger-key-positions = <1 2 0 3 4 5>;
        };

        lt_right: lt_right {
            compatible = "zmk,behavior-hold-tap";
            label = "LT_RIGHT";
            bindings = <&mo>, <&moff_tap>;

            #binding-cells = <2>;
            tapping-term-ms = <200>;
            flavor = "balanced";
        };

        hrml_alt: hrml_alt {
            compatible = "zmk,behavior-hold-tap";
            label = "HRML_ALT";
            bindings = <&ml>, <&moff_tap>;

            #binding-cells = <2>;
            tapping-term-ms = <200>;
            flavor = "balanced";
            hold-trigger-key-positions = <19 20 43 44 28 16 39 40 27 15 17 29 41 55>;
        };

        hrml_ctrl: hrml_ctrl {
            compatible = "zmk,behavior-hold-tap";
            label = "HRML_CTRL";
            bindings = <&ml>, <&moff_tap>;

            #binding-cells = <2>;
            tapping-term-ms = <200>;
            flavor = "balanced";
            hold-trigger-key-positions = <18 19 20 21 22 30 31 32 33 34 42 43 44 45 46 54 26 25 15 14 13 51 27 55>;
        };

        hrms: hrms {
            compatible = "zmk,behavior-hold-tap";
            label = "HRMS";
            bindings = <&ml>, <&moff_tap>;

            #binding-cells = <2>;
            tapping-term-ms = <200>;
            flavor = "balanced";
            hold-while-undecided;
            hold-trigger-key-positions = <25 26 27 28 15 14 13 31 18 19 21 22 30 31 32 33 34 42 43 44 45 46 20 51 54 55>;
        };

        mlt: mlt {
            compatible = "zmk,behavior-hold-tap";
            label = "MLT";
            bindings = <&mo>, <&moff_tap>;

            #binding-cells = <2>;
            tapping-term-ms = <200>;
            flavor = "tap-preferred";
            hold-while-undecided;
        };

        lang: lang {
            compatible = "zmk,behavior-mod-morph";
            label = "LANG";
            bindings = <&layer_ru>, <&layer_en>;

            #binding-cells = <0>;
            mods = <(MOD_LSFT)>;
        };

        lg: lg {
            compatible = "zmk,behavior-hold-tap";
            label = "LG";
            bindings = <&layer_en>, <&layer_ru>;

            #binding-cells = <2>;
            tapping-term-ms = <150>;
            flavor = "tap-preferred";
        };
    };

    zip_auto_mouse: zip_auto_mouse {
        compatible = "zmk,input-processor-temp-layer";
        #input-processor-cells = <2>;
        require-prior-idle-ms = <100>;
        excluded-positions = <14 15 16 25 26 27 28 30 37 38 39 40 42 51 56>;
    };

    keymap {
        compatible = "zmk,keymap";

        En {
            bindings = <
&mt F1 N1     &mt F2 N2              &mt F3 N3         &mt F4 N4                &mt F5 N5                &mt F6 N6                                            &mt F7 N7       &mt F8 N8      &mt F9 N9                 &mt F10 N0         &mt F11 MINUS      &mt F12 EQUAL
&none         &mt Q Q                &mt W W           &mt U U                  &mmt LC(R) A             &mt LC(T) K_CANCEL                                   &mt Z Z         &mt V V        &mt K K                   &mt D D            &kp K_CANCEL       &none
&kp K_CANCEL  &hrml_slow LEFT_GUI C  &hrml LEFT_ALT I  &hrml_left LEFT_SHIFT E  &hrml LCTRL O            &en_com_mt LC(F) 0                                   &mt L L         &hrml RCTRL N  &hrml_right LEFT_SHIFT T  &hrml_slow RALT S  &hrml_slow RGUI H  &kp K_CANCEL
&none         &mmt LC(Z) F           &mmt LC(X) Y      &mmt LC(C) X             &mmt LC(V) SINGLE_QUOTE  &en_dot_mt LG(V) 0                                   &mt B B         &mt M M        &mt P P                   &mt G G            &mt LC(SLASH) J    &none
                                     &kp LS(F7)        &kp F7                   &lg 0 0                  &lt 10 SPACE        &sl 14              &osm LSHIFT  &lt_right 12 R  &bspc_morph    &kp F2                    &kp LS(F2)
                                                                                                                             &kp C_PLAY_PAUSE    &trans
            >;

            sensor-bindings = <&inc_dec_kp C_VOL_UP C_VOL_DN>;
        };

        En_CW {
            bindings = <
&trans            &trans                       &trans                      &trans                         &trans                   &trans                                    &trans                &trans               &trans                          &trans                   &trans                   &trans
&trans            &mt (LS(Q)) LS(Q)            &mt (LS(W)) LS(W)           &mt (LS(U)) LS(U)              &mmt (LC(R)) LS(A)       &mt LC(T) K_CANCEL                        &mt (LS(Z)) LS(Z)     &mt (LS(V)) LS(V)    &mt (LS(K)) LS(K)               &mt (LS(D)) LS(D)        &kp LS(K_CANCEL)         &trans
&kp LS(K_CANCEL)  &hrml_slow (LEFT_GUI) LS(C)  &hrml_alt (LEFT_ALT) LS(I)  &hrml_left (LEFT_SHIFT) LS(E)  &hrml (LCTRL) LS(O)      &en_com_mt LC(F) 0                        &mt (LS(L)) LS(L)     &hrml (RCTRL) LS(N)  &hrml_right (LEFT_SHIFT) LS(T)  &hrml_slow (RALT) LS(S)  &hrml_slow (RGUI) LS(H)  &kp LS(K_CANCEL)
&trans            &mmt (LC(Z)) LS(F)           &mmt (LC(X)) LS(Y)          &mmt (LC(C)) LS(X)             &mmt LC(V) SINGLE_QUOTE  &en_dot_mt LG(V) 0                        &mt (LS(B)) LS(B)     &mt (LS(M)) LS(M)    &mt (LS(P)) LS(P)               &mt (LS(G)) LS(G)        &mt (LC(SLASH)) LS(J)    &trans
                                               &trans                      &trans                         &trans                   &en_lt_cw_off 10 SPACE  &sl 14    &trans  &lt_right (12) LS(R)  &trans               &trans                          &trans
                                                                                                                                                           &trans    &trans
            >;
        };

        Ru {
            bindings = <
&mt N1 F1                        &mt N2 F2                                &mt N3 F3                         &mt N4 F4                             &mt N5 F5                    &mt N6 F6                                       &mt N7 F7                          &mt N8 F8                          &mt N9 F9                              &mt N0 F10                           &mt MINUS F11                            &mt EQUAL F12
&none                            &mt RU_CYRILLIC_TSE RU_CYRILLIC_TSE      &soft 0 0                         &mt RU_CYRILLIC_YA RU_CYRILLIC_YA     &mmt LC(R) RU_CYRILLIC_A     &mt LC(T) RU_CYRILLIC_YU                        &mt RU_CYRILLIC_ZE RU_CYRILLIC_ZE  &mt RU_CYRILLIC_VE RU_CYRILLIC_VE  &mt RU_CYRILLIC_KA RU_CYRILLIC_KA      &mt RU_CYRILLIC_DE RU_CYRILLIC_DE    &mt RU_CYRILLIC_SHCHA RU_CYRILLIC_SHCHA  &none
&mt RU_CYRILLIC_E RU_CYRILLIC_E  &hrml_slow LEFT_GUI RU_CYRILLIC_SHORT_I  &hrml_alt LEFT_ALT RU_CYRILLIC_I  &hrml_left LEFT_SHIFT RU_CYRILLIC_IE  &hrml LCTRL RU_CYRILLIC_O    &ru_com_mt LC(F) 0                              &mt RU_CYRILLIC_EL RU_CYRILLIC_EL  &hrml RCTRL RU_CYRILLIC_EN         &hrml_right LEFT_SHIFT RU_CYRILLIC_TE  &hrml_slow RALT RU_CYRILLIC_ES       &hrml_slow RGUI RU_CYRILLIC_CHE          &mt RU_CYRILLIC_SHA RU_CYRILLIC_SHA
&none                            &mmt LC(Z) RU_CYRILLIC_EF                &mmt LC(X) RU_CYRILLIC_U          &mmt LC(C) RU_CYRILLIC_HA             &mmt LC(V) RU_CYRILLIC_YERU  &ru_dot_mt LG(V) 0                              &mt RU_CYRILLIC_BE RU_CYRILLIC_BE  &mt RU_CYRILLIC_EM RU_CYRILLIC_EM  &mt RU_CYRILLIC_PE RU_CYRILLIC_PE      &mt RU_CYRILLIC_GHE RU_CYRILLIC_GHE  &mt LC(SLASH) RU_CYRILLIC_ZHE            &none
                                                                          &trans                            &trans                                &trans                       &lt 10 SPACE              &sl 14    &osm LSHFT  &lt_right 12 RU_CYRILLIC_ER        &trans                             &trans                                 &trans
                                                                                                                                                                                                         &trans    &trans
            >;
        };

        Ru_CW {
            bindings = <
&trans                 &trans                                         &trans                                  &trans                                       &trans                             &trans                                            &trans                                       &trans                                       &trans                                       &trans                                         &trans                                             &trans
&trans                 &mt (LS(RU_CYRILLIC_TSE)) LS(RU_CYRILLIC_TSE)  &soft_caps 0 0                          &mt (LS(RU_CYRILLIC_YA)) LS(RU_CYRILLIC_YA)  &mmt (LC(R)) LS(RU_CYRILLIC_A)     &mt (LC(T)) LS(RU_CYRILLIC_YU)                    &mt (LS(RU_CYRILLIC_ZE)) LS(RU_CYRILLIC_ZE)  &mt (LS(RU_CYRILLIC_VE)) LS(RU_CYRILLIC_VE)  &mt (LS(RU_CYRILLIC_KA)) LS(RU_CYRILLIC_KA)  &mt (LS(RU_CYRILLIC_DE)) LS(RU_CYRILLIC_DE)    &mt (LS(RU_CYRILLIC_SHCHA)) LS(RU_CYRILLIC_SHCHA)  &trans
&kp LS(RU_CYRILLIC_E)  &hrml_slow (LEFT_GUI) LS(RU_CYRILLIC_SHORT_I)  &hrml_alt (LEFT_ALT) LS(RU_CYRILLIC_I)  &hrml_left (LEFT_SHIFT) LS(RU_CYRILLIC_IE)   &hrml (LCTRL) LS(RU_CYRILLIC_O)    &ru_com_mt LC(F) 0                                &mt (LS(RU_CYRILLIC_EL)) LS(RU_CYRILLIC_EL)  &hrml (RCTRL) LS(RU_CYRILLIC_EN)             &hrml_right (LEFT_SHIFT) LS(RU_CYRILLIC_TE)  &hrml_slow (RALT) LS(RU_CYRILLIC_ES)           &hrml_slow (RGUI) LS(RU_CYRILLIC_CHE)              &mt (LS(RU_CYRILLIC_SHA)) LS(RU_CYRILLIC_SHA)
&trans                 &mmt (LC(Z)) LS(RU_CYRILLIC_EF)                &mmt (LC(X)) LS(RU_CYRILLIC_U)          &mmt (LC(C)) LS(RU_CYRILLIC_HA)              &mmt (LC(V)) LS(RU_CYRILLIC_YERU)  &ru_dot_mt LG(V) 0                                &mt (LS(RU_CYRILLIC_BE)) LS(RU_CYRILLIC_BE)  &mt (LS(RU_CYRILLIC_EM)) LS(RU_CYRILLIC_EM)  &mt (LS(RU_CYRILLIC_PE)) LS(RU_CYRILLIC_PE)  &mt (LS(RU_CYRILLIC_GHE)) LS(RU_CYRILLIC_GHE)  &mt (LC(SLASH)) LS(RU_CYRILLIC_ZHE)                &trans
                                                                      &trans                                  &trans                                       &trans                             &ru_lt_cw_off 10 SPACE          &trans    &trans  &lt_right (12) LS(RU_CYRILLIC_ER)            &trans                                       &trans                                       &trans
                                                                                                                                                                                                                              &trans    &trans
            >;
        };

        AutoMouse {
            bindings = <
&trans  &trans            &trans            &trans              &trans         &trans                            &trans     &trans  &trans    &trans     &trans  &trans
&trans  &trans            &trans            &trans              &trans         &trans                            &trans     &trans  &trans    &trans     &trans  &trans
&trans  &hrms LEFT_GUI C  &hrms LEFT_ALT I  &hrms LEFT_SHIFT E  &hrms LCTRL O  &trans                            &mlt 24 L  &trans  &trans    &trans     &trans  &trans
&trans  &trans            &trans            &trans              &trans         &trans                            &mlt 24 B  &trans  &trans    &trans     &trans  &trans
                          &trans            &trans              &trans         &ms_space 10 0  &trans    &trans  &trans     &trans  &mkp MB2  &mkp MCLK
                                                                                               &trans    &trans
            >;
        };

        AutoMouse_ru {
            bindings = <
&trans  &trans                              &trans                        &trans                           &trans                     &trans                    &trans                  &trans  &trans    &trans  &trans  &trans
&trans  &trans                              &trans                        &trans                           &trans                     &trans                    &trans                  &trans  &trans    &trans  &trans  &trans
&trans  &hrms LEFT_GUI RU_CYRILLIC_SHORT_I  &hrms LEFT_ALT RU_CYRILLIC_I  &hrms LEFT_SHIFT RU_CYRILLIC_IE  &hrms LCTRL RU_CYRILLIC_O  &trans                    &mlt 24 RU_CYRILLIC_EL  &trans  &trans    &trans  &trans  &trans
&trans  &trans                              &trans                        &trans                           &trans                     &trans                    &mlt 24 RU_CYRILLIC_BE  &trans  &trans    &trans  &trans  &trans
                                            &trans                        &trans                           &trans                     &trans  &trans    &trans  &trans                  &trans  &mkp MB2  &trans
                                                                                                                                              &trans    &trans
            >;
        };

        M1 {
            bindings = <
&trans                &trans                      &trans                        &trans                 &trans                   &trans                                                       &trans              &trans              &trans              &trans               &trans                 &trans
&trans                &kp_m1 RU_CYRILLIC_TSE      &kp_m1 RU_CYRILLIC_SOFT_SIGN  &kp_m1 RU_CYRILLIC_YA  &kp_m1 RU_CYRILLIC_A     &kp_m1 RU_CYRILLIC_YU                                        &kp RU_CYRILLIC_ZE  &kp RU_CYRILLIC_VE  &kp RU_CYRILLIC_KA  &kp RU_CYRILLIC_DE   &kp RU_CYRILLIC_SHCHA  &trans
&kp_m1 RU_CYRILLIC_E  &kp_m1 RU_CYRILLIC_SHORT_I  &kp_m1 RU_CYRILLIC_I          &kp_m1 RU_CYRILLIC_IE  &kp_m1 RU_CYRILLIC_O     &kp_m1 LS(N6)                                                &kp RU_CYRILLIC_EL  &kp RU_CYRILLIC_EN  &kp RU_CYRILLIC_TE  &kp RU_CYRILLIC_ES   &kp RU_CYRILLIC_CHE    &kp RU_CYRILLIC_SHA
&trans                &kp_m1 RU_CYRILLIC_EF       &kp_m1 RU_CYRILLIC_U          &kp_m1 RU_CYRILLIC_HA  &kp_m1 RU_CYRILLIC_YERU  &kp_m1 LS(RU_N7)                                             &kp RU_CYRILLIC_BE  &kp RU_CYRILLIC_EM  &kp RU_CYRILLIC_PE  &kp RU_CYRILLIC_GHE  &kp RU_CYRILLIC_ZHE    &trans
                                                  &trans                        &trans                 &overoff_ru              &nav_set 10 4          &overoff_sl 6 14    &switch_mon BSPC  &back_num 12 8      &overoff_en         &trans              &trans
                                                                                                                                                       &trans              &trans
            >;
        };

        M2 {
            bindings = <
&trans             &trans                   &trans                     &trans              &trans                &trans                                                         &trans                 &trans                 &trans                 &trans                  &trans                    &trans
&trans             &kp RU_CYRILLIC_TSE      &kp RU_CYRILLIC_SOFT_SIGN  &kp RU_CYRILLIC_YA  &kp RU_CYRILLIC_A     &kp RU_CYRILLIC_YU                                             &kp_m2 RU_CYRILLIC_ZE  &kp_m2 RU_CYRILLIC_VE  &kp_m2 RU_CYRILLIC_KA  &kp_m2 RU_CYRILLIC_DE   &kp_m2 RU_CYRILLIC_SHCHA  &trans
&kp RU_CYRILLIC_E  &kp RU_CYRILLIC_SHORT_I  &kp RU_CYRILLIC_I          &kp RU_CYRILLIC_IE  &kp RU_CYRILLIC_O     &kp LS(N6)                                                     &kp_m2 RU_CYRILLIC_EL  &kp_m2 RU_CYRILLIC_EN  &kp_m2 RU_CYRILLIC_TE  &kp_m2 RU_CYRILLIC_ES   &kp_m2 RU_CYRILLIC_CHE    &kp_m2 RU_CYRILLIC_SHA
&trans             &kp RU_CYRILLIC_EF       &kp RU_CYRILLIC_U          &kp RU_CYRILLIC_HA  &kp RU_CYRILLIC_YERU  &kp LS(RU_N7)                                                  &kp_m2 RU_CYRILLIC_BE  &kp_m2 RU_CYRILLIC_EM  &kp_m2 RU_CYRILLIC_PE  &kp_m2 RU_CYRILLIC_GHE  &kp_m2 RU_CYRILLIC_ZHE    &trans
                                            &trans                     &trans              &overoff_ru           &nav_set 10 4       &overoff_sl 7 14    &switch_mon BACKSPACE  &back_num 12 8         &overoff_en            &trans                 &trans
                                                                                                                                     &trans              &trans
            >;
        };

        Mod {
            bindings = <
&trans  &trans            &trans            &trans             &trans        &trans                            &trans                 &trans        &trans             &trans            &trans               &trans
&trans  &kp Q             &kp W             &moff_kp E         &kp R         &kp T                             &kp Y                  &kp U         &kp I              &kp O             &kp P                &trans
&trans  &hrm_slow LGUI A  &hrm_slow LALT S  &hrm LEFT_SHIFT D  &hrm LCTRL F  &kp G                             &kp H                  &hrm RCTRL J  &hrm LEFT_SHIFT K  &hrm_slow RALT L  &hrm_slow RGUI SEMI  &trans
&trans  &mmt LC(Z) Z      &mmt LC(X) X      &mmt LC(C) C       &mmt LC(V) V  &kp B                             &kp N                  &kp M         &kp COMMA          &kp DOT           &kp SLASH            &trans
                          &trans            &trans             &trans        &space_lt 10 0  &trans    &trans  &lt_right 12 K_CANCEL  &trans        &trans             &trans
                                                                                             &trans    &trans
            >;
        };

        Mod_ru {
            bindings = <
&trans  &trans  &trans  &trans  &trans  &trans                    &trans  &trans  &trans  &trans  &trans  &trans
&trans  &trans  &trans  &trans  &trans  &trans                    &trans  &trans  &trans  &trans  &trans  &trans
&trans  &trans  &trans  &trans  &trans  &trans                    &trans  &trans  &trans  &trans  &trans  &trans
&trans  &trans  &trans  &trans  &trans  &trans                    &trans  &trans  &trans  &trans  &trans  &trans
                &trans  &trans  &trans  &trans  &trans    &trans  &trans  &trans  &trans  &trans
                                                &trans    &trans
            >;
        };

        Nav {
            bindings = <
&trans        &trans                        &trans                         &trans                 &trans                    &trans                                             &trans      &trans         &trans     &trans          &trans      &trans
&trans        &trans                        &macro_unsafe_en               &kp LC(LS(LA(TAB)))    &kp LS(LC(LA(LG(F1))))    &testops                                           &none       &kp LA(LS(S))  &kp UP     &kp LC(LA(F8))  &kp DELETE  &trans
&kp CAPSLOCK  &kp ESC                       &kp ENTER                      &kp LSHIFT             &mod_dtap LCTRL LEFT_GUI  &zeros_macro                                       &kp K_APP   &kp LEFT       &kp DOWN   &kp RIGHT       &kp END     &trans
&trans        &mt (LC(Z)) LC(LEFT_BRACKET)  &mt (LC(X)) LC(RIGHT_BRACKET)  &mt (LC(C)) LS(LC(C))  &mt LC(V) TAB             &mt (LG(V)) LS(LC(LG(F9)))                         &kp LC(F8)  &kp HOME       &kp PG_DN  &kp PG_UP       &trans      &trans
                                            &trans                         &trans                 &trans                    &mo 10                      &none     &layer_on 1  &mo 12      &trans         &trans     &trans
                                                                                                                                                        &trans    &trans
            >;
        };

        Nav_ru {
            bindings = <
&trans  &trans  &trans            &trans  &trans  &trans                         &trans  &trans  &trans  &trans  &trans  &trans
&trans  &trans  &macro_unsafe_ru  &trans  &trans  &trans                         &trans  &trans  &trans  &trans  &trans  &trans
&trans  &trans  &trans            &trans  &trans  &trans                         &trans  &trans  &trans  &trans  &trans  &trans
&trans  &trans  &trans            &trans  &trans  &trans                         &trans  &trans  &trans  &trans  &trans  &trans
                &trans            &trans  &trans  &trans  &trans    &layer_on 3  &trans  &trans  &trans  &trans
                                                          &trans    &trans
            >;
        };

        Num {
            bindings = <
&trans  &trans         &trans           &trans           &trans         &trans                                  &trans    &trans     &trans      &trans        &trans        &trans
&trans  &kp MINUS      &mt F7 N7        &mt F8 N8        &mt F9 N9      &mt F10 EQUAL                           &trans    &trans     &trans      &trans        &trans        &trans
&none   &zero 0 N0     &mt F1 N1        &mt F2 NUMBER_2  &mt F3 N3      &trans                                  &kp PLUS  &kp LCTRL  &kp LSHIFT  &kp LEFT_ALT  &kp LEFT_GUI  &trans
&trans  &mt F10 UNDER  &mt F4 NUMBER_4  &mt F5 NUMBER_5  &mt F6 N6      &trans                                  &trans    &kp UNDER  &none       &none         &trans        &trans
                       &trans           &trans           &mt F11 MINUS  &lt 10 SPACE   &mt F12 EQUAL    &trans  &mo 12    &trans     &trans      &trans
                                                                                       &trans           &trans
            >;
        };

        Num_ru {
            bindings = <
&trans  &trans  &trans  &trans  &trans  &trans                    &trans  &trans  &trans  &trans  &trans  &trans
&trans  &trans  &trans  &trans  &trans  &trans                    &trans  &trans  &trans  &trans  &trans  &trans
&trans  &trans  &trans  &trans  &trans  &trans                    &trans  &trans  &trans  &trans  &trans  &trans
&trans  &trans  &trans  &trans  &trans  &trans                    &trans  &trans  &trans  &trans  &trans  &trans
                &trans  &trans  &trans  &trans  &trans    &trans  &trans  &trans  &trans  &trans
                                                &trans    &trans
            >;
        };

        App {
            bindings = <
&trans                        &trans                                 &trans                                    &trans                                 &trans                     &trans                                              &trans             &trans             &trans                 &trans               &trans                     &trans
&trans                        &kp LA(LC(LS(P)))                      &vm_en (LS(LA(LC(LG(W))))) LS(LA(LC(W)))  &mt (LS(LA(LC(LG(E))))) LA(LS(LC(E)))  &mt (LG(R)) LS(LA(LC(R)))  &mt (LC(T)) LS(LA(LC(T)))                           &kp LS(LA(LC(Y)))  &kp LS(LA(LC(U)))  &kp LS(LA(LC(I)))      &kp LS(LA(LC(O)))    &kp LS(LA(LC(P)))          &trans
&kp LS(LA(LC(LEFT_BRACKET)))  &mt (LS(LA(LC(LG(A))))) LS(LA(LC(A)))  &mt (LS(LA(LC(LG(S))))) LS(LA(LC(S)))     &mt (LS(LA(LC(LG(D))))) LC(LA(LS(D)))  &kp LS(LA(LC(F)))          &mt (LC(F)) LA(LS(LC(G)))                           &kp LS(LA(LC(H)))  &kp LS(LA(LC(J)))  &kp LS(LA(LC(K)))      &kp LS(LA(LC(L)))    &kp LS(LA(LC(SEMICOLON)))  &kp LS(LA(LC(RIGHT_BRACKET)))
&trans                        &mt (LC(Z)) LC(LA(LS(Z)))              &mt (LC(X)) LA(LS(LC(X)))                 &mt (LC(C)) LS(LA(LC(C)))              &mt (LC(V)) LS(LC(LG(V)))  &mt (LG(V)) LS(LA(LC(B)))                           &kp LS(LA(LC(N)))  &kp LS(LC(LA(M)))  &kp LS(LA(LC(COMMA)))  &kp LS(LA(LC(DOT)))  &kp LS(LC(LA(SLASH)))      &trans
                                                                     &trans                                    &trans                                 &trans                     &trans                     &sl 14    &kp LA(ENTER)  &alt_spc_en        &trans             &trans                 &trans
                                                                                                                                                                                                            &trans    &trans
            >;
        };

        App_ru {
            bindings = <
&trans  &trans  &trans                                    &trans  &trans  &trans                    &trans       &trans  &trans  &trans  &trans  &trans
&trans  &trans  &vm_ru (LS(LA(LC(LG(W))))) LS(LA(LC(W)))  &trans  &trans  &trans                    &trans       &trans  &trans  &trans  &trans  &trans
&trans  &trans  &trans                                    &trans  &trans  &trans                    &trans       &trans  &trans  &trans  &trans  &trans
&trans  &trans  &trans                                    &trans  &trans  &trans                    &trans       &trans  &trans  &trans  &trans  &trans
                &trans                                    &trans  &trans  &trans  &trans    &trans  &alt_spc_ru  &trans  &trans  &trans
                                                                                  &trans    &trans
            >;
        };

        Sym {
            bindings = <
&trans  &trans  &trans                &trans         &trans                 &trans                         &trans            &trans            &trans        &trans             &trans  &trans
&trans  &trans  &none                 &kp AMPERSAND  &kp CARET              &trans                         &trans            &kp LEFT_BRACKET  &kp ASTERISK  &kp RIGHT_BRACKET  &trans  &trans
&trans  &trans  &kp LEFT_PARENTHESIS  &kp AT         &kp RIGHT_PARENTHESIS  &kp PERCENT                    &ru_kp RU_NUMERO  &kp LEFT_BRACE    &kp DOLLAR    &kp RIGHT_BRACE    &trans  &trans
&trans  &trans  &kp TILDE             &kp HASH       &en_code               &none                          &trans            &kp LESS_THAN     &arrow_en     &kp GREATER_THAN   &trans  &trans
                &trans                &trans         &trans                 &trans       &trans    &trans  &trans            &trans            &trans        &trans
                                                                                         &trans    &trans
            >;
        };

        Sym_ru {
            bindings = <
&trans  &trans  &trans                &trans            &trans        &trans                            &trans         &trans               &trans         &trans                &trans  &trans
&trans  &trans  &none                 &en_kp AMPERSAND  &en_kp CARET  &trans                            &trans         &en_kp LEFT_BRACKET  &kp ASTRK      &en_kp RIGHT_BRACKET  &trans  &trans
&trans  &trans  &kp LEFT_PARENTHESIS  &en_kp AT         &kp RPAR      &kp RU_PERCENT                    &kp RU_NUMERO  &en_kp LEFT_BRACE    &en_kp DOLLAR  &en_kp RIGHT_BRACE    &trans  &trans
&trans  &trans  &en_kp TILDE          &en_kp HASH       &ru_code      &none                             &trans         &en_kp LESS_THAN     &arrow_ru      &en_kp GREATER_THAN   &trans  &trans
                &trans                &trans            &trans        &trans          &trans    &trans  &trans         &trans               &trans         &trans
                                                                                      &trans    &trans
            >;
        };

        Fn {
            bindings = <
&trans  &trans   &trans  &trans  &trans  &trans                     &trans  &trans     &trans          &trans    &trans        &trans
&trans  &trans   &kp F7  &kp F8  &kp F9  &trans                     &trans  &trans     &trans          &trans    &trans        &trans
&trans  &kp F10  &kp F1  &kp F2  &kp F3  &kp F12                    &trans  &kp LCTRL  &kp LEFT_SHIFT  &kp LALT  &kp LEFT_GUI  &trans
&trans  &kp F11  &kp F4  &kp F5  &kp F6  &kp F11                    &trans  &trans     &trans          &trans    &trans        &trans
                 &trans  &trans  &trans  &trans   &trans    &trans  &trans  &trans     &trans          &trans
                                                  &trans    &trans
            >;
        };

        OS {
            bindings = <
&trans       &trans        &trans            &trans                    &trans                &trans                                  &trans        &trans   &trans  &trans  &trans      &trans
&trans       &bt_set_en 2  &kp LA(LC(N1))    &kp LA(LC(N2))            &kp LC(LA(NUMBER_3))  &kp LC(LA(NUMBER_4))                    &trans        &none    &trans  &trans  &bt BT_CLR  &trans
&trans       &bt_set_en 1  &kp C_PLAY_PAUSE  &kp LA(LC(N1))            &kp C_VOLUME_UP       &kp C_BRI_UP                            &out OUT_BLE  &kp F24  &trans  &trans  &soft_off   &trans
&bootloader  &bt_set_en 0  &none             &kp LC(LS(LEFT_BRACKET))  &kp C_VOL_DN          &kp C_BRI_DN                            &out OUT_USB  &kp F23  &trans  &trans  &trans      &bootloader
                           &trans            &bootloader               &trans                &trans                &trans    &trans  &trans        &trans   &trans  &trans
                                                                                                                   &trans    &trans
            >;
        };

        OS_ru {
            bindings = <
&trans  &trans        &trans  &trans  &trans  &trans                    &trans  &trans  &trans  &trans  &trans  &trans
&trans  &bt_set_ru 2  &trans  &trans  &trans  &trans                    &trans  &trans  &trans  &trans  &trans  &trans
&trans  &bt_set_ru 1  &trans  &trans  &trans  &trans                    &trans  &trans  &trans  &trans  &trans  &trans
&trans  &bt_set_ru 0  &trans  &trans  &trans  &trans                    &trans  &trans  &trans  &trans  &trans  &trans
                      &trans  &trans  &trans  &trans  &trans    &trans  &trans  &trans  &trans  &trans
                                                      &trans    &trans
            >;
        };

        Slower {
            bindings = <
&trans  &trans  &trans  &trans  &trans  &trans                    &trans  &trans  &trans  &trans  &trans  &trans
&trans  &trans  &trans  &trans  &trans  &trans                    &trans  &trans  &trans  &trans  &trans  &trans
&trans  &trans  &trans  &trans  &trans  &trans                    &trans  &trans  &trans  &trans  &trans  &trans
&trans  &trans  &trans  &trans  &trans  &trans                    &trans  &trans  &trans  &trans  &trans  &trans
                &trans  &trans  &trans  &trans  &trans    &trans  &trans  &trans  &trans  &trans
                                                &trans    &trans
            >;
        };

        Faster {
            bindings = <
&trans  &trans  &trans  &trans  &trans  &trans                    &trans  &trans  &trans  &trans  &trans  &trans
&trans  &trans  &trans  &trans  &trans  &trans                    &trans  &trans  &trans  &trans  &trans  &trans
&trans  &trans  &trans  &trans  &trans  &trans                    &trans  &trans  &trans  &trans  &trans  &trans
&trans  &trans  &trans  &trans  &trans  &trans                    &trans  &trans  &trans  &trans  &trans  &trans
                &trans  &trans  &trans  &trans  &trans    &trans  &trans  &trans  &trans  &trans
                                                &trans    &trans
            >;
        };

        Click {
            bindings = <
&trans  &trans  &trans  &trans  &trans  &trans                    &trans  &trans  &trans  &trans  &trans  &trans
&trans  &trans  &click  &trans  &trans  &trans                    &trans  &trans  &trans  &trans  &trans  &trans
&trans  &trans  &trans  &trans  &trans  &trans                    &trans  &trans  &trans  &trans  &trans  &trans
&trans  &trans  &trans  &trans  &trans  &trans                    &trans  &trans  &trans  &trans  &trans  &trans
                &trans  &trans  &trans  &trans  &trans    &trans  &trans  &trans  &trans  &trans
                                                &trans    &trans
            >;
        };

        Scroll {
            bindings = <
&trans  &trans  &trans  &trans  &trans  &trans                    &trans  &trans  &trans  &trans  &trans  &trans
&trans  &trans  &trans  &trans  &trans  &trans                    &trans  &trans  &trans  &trans  &trans  &trans
&trans  &trans  &trans  &trans  &trans  &trans                    &trans  &trans  &trans  &trans  &trans  &trans
&trans  &trans  &trans  &trans  &trans  &trans                    &trans  &trans  &trans  &trans  &trans  &trans
                &trans  &trans  &trans  &trans  &trans    &trans  &trans  &trans  &trans  &trans
                                                &trans    &trans
            >;
        };
    };

    conditional_layers {
        compatible = "zmk,conditional-layers";

        OS {
            if-layers = <2 19>;
            then-layer = <20>;
        };

        Num {
            if-layers = <2 12>;
            then-layer = <13>;
        };

        App {
            if-layers = <2 14>;
            then-layer = <15>;
        };

        Nav {
            if-layers = <2 10>;
            then-layer = <11>;
        };

        Sym_Ru {
            if-layers = <2 16>;
            then-layer = <17>;
        };

        Sym {
            if-layers = <12 10>;
            then-layer = <16>;
        };

        AutoMouse {
            if-layers = <2 4>;
            then-layer = <5>;
        };

        Mod {
            if-layers = <2 8>;
            then-layer = <9>;
        };
    };
};

&trackball_listener {
    input-processors = <&zip_auto_mouse 4 30000>, <&zip_xy_scaler 2 5>;

    scroller {
        layers = <10 24>;
        input-processors =
            <&zip_xy_transform INPUT_TRANSFORM_Y_INVERT>,
            <&zip_xy_scaler 1 64>,
            <&zip_xy_to_scroll_mapper>;
    };

    faster {
        layers = <22>;
        input-processors = <&zip_xy_scaler 2 1>;
    };

    slower {
        layers = <8 21>;
        input-processors = <&zip_xy_scaler 1 4>;
    };
};
